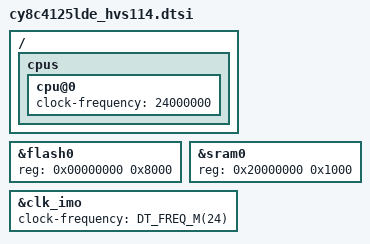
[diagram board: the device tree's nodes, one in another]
/*
 * SPDX-FileCopyrightText: Copyright (c) 2026 Infineon Technologies AG,
 * SPDX-FileCopyrightText: or an affiliate of Infineon Technologies AG. All rights reserved.
 *
 * SPDX-License-Identifier: Apache-2.0
 */

#include "../psoc4hvms64k/psoc4hvms64k.48-qfn.dtsi"

&flash0 {
	reg = <0x00000000 0x8000>;
	ranges = <0x0 0x0 0x8000>;
};

&sram0 {
	reg = <0x20000000 0x1000>;
};

&clk_imo {
	clock-frequency = <DT_FREQ_M(24)>;
};

/ {
	cpus {
		cpu@0 {
			clock-frequency = <24000000>;
		};
	};
};
